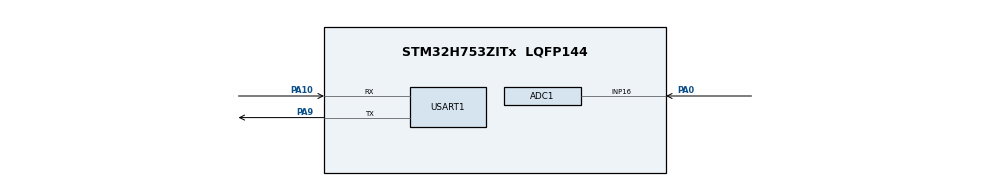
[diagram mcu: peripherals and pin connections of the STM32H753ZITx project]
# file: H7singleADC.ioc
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ADC1.Channel-0\#ChannelRegularConversion=ADC_CHANNEL_16
ADC1.ContinuousConvMode=ENABLE
ADC1.NbrOfConversionFlag=1
ADC1.OffsetNumber-0\#ChannelRegularConversion=ADC_OFFSET_NONE
ADC1.OffsetSignedSaturation-0\#ChannelRegularConversion=DISABLE
ADC1.Rank-0\#ChannelRegularConversion=1
ADC1.SamplingTime-0\#ChannelRegularConversion=ADC_SAMPLETIME_1CYCLE_5
ADC1.master=1
Dma.ADC1.0.Direction=DMA_PERIPH_TO_MEMORY
Dma.ADC1.0.EventEnable=DISABLE
Dma.ADC1.0.FIFOMode=DMA_FIFOMODE_DISABLE
Dma.ADC1.0.Instance=DMA1_Stream0
Dma.ADC1.0.MemDataAlignment=DMA_MDATAALIGN_HALFWORD
Dma.ADC1.0.MemInc=DMA_MINC_ENABLE
Dma.ADC1.0.Mode=DMA_CIRCULAR
Dma.ADC1.0.PeriphDataAlignment=DMA_PDATAALIGN_HALFWORD
Dma.ADC1.0.PeriphInc=DMA_PINC_DISABLE
Dma.ADC1.0.Polarity=HAL_DMAMUX_REQ_GEN_RISING
Dma.ADC1.0.Priority=DMA_PRIORITY_LOW
Dma.ADC1.0.RequestNumber=1
Dma.ADC1.0.SignalID=NONE
Dma.ADC1.0.SyncEnable=DISABLE
Dma.ADC1.0.SyncPolarity=HAL_DMAMUX_SYNC_NO_EVENT
Dma.ADC1.0.SyncRequestNumber=1
Dma.ADC1.0.SyncSignalID=NONE
Dma.Request0=ADC1
Mcu.Family=STM32H7
Mcu.Name=STM32H753ZITx
Mcu.Package=LQFP144
NVIC.ADC_IRQn=true\:0\:0\:false\:false\:true\:true\:true\:true
NVIC.DMA1_Stream0_IRQn=true\:0\:0\:false\:false\:true\:false\:true\:true
NVIC.PriorityGroup=NVIC_PRIORITYGROUP_4
PA0.Mode=IN16-Single-Ended
PA0.Signal=ADC1_INP16
PA10.Mode=Asynchronous
PA10.Signal=USART1_RX
PA9.Mode=Asynchronous
PA9.Signal=USART1_TX
ProjectManager.HeapSize=0x200
ProjectManager.StackSize=0x400
ProjectManager.TargetToolchain=STM32CubeIDE
RCC.ADCFreq_Value=129000000
RCC.APB1Freq_Value=64000000
RCC.APB2Freq_Value=64000000
RCC.APB3Freq_Value=64000000
RCC.APB4Freq_Value=64000000
RCC.CortexFreq_Value=64000000
RCC.HCLKFreq_Value=64000000
RCC.SYSCLKFreq_VALUE=64000000
RCC.USBFreq_Value=129000000
USART1.VirtualMode-Asynchronous=VM_ASYNC
board=custom

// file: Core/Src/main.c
/* USER CODE BEGIN Header */
/**
  ******************************************************************************
  * @file           : main.c
  * @brief          : Main program body
  ******************************************************************************
  * @attention
  *
  * Copyright (c) 2024 STMicroelectronics.
  * All rights reserved.
  *
  * This software is licensed under terms that can be found in the LICENSE file
  * in the root directory of this software component.
  * If no LICENSE file comes with this software, it is provided AS-IS.
  *
  ******************************************************************************
  */
/* USER CODE END Header */
#include "main.h"

/* USER CODE BEGIN PM */
#define ADC_BUF_LEN 4096
/* USER CODE END PM */

ADC_HandleTypeDef hadc1;
DMA_HandleTypeDef hdma_adc1;

UART_HandleTypeDef huart1;

/* USER CODE BEGIN PV */
uint16_t adc_buf[ADC_BUF_LEN];
/* USER CODE END PV */

void SystemClock_Config(void);
static void MX_GPIO_Init(void);
static void MX_DMA_Init(void);
static void MX_ADC1_Init(void);
static void MX_USART1_UART_Init(void);

int main(void)
{

  /* MCU Configuration--------------------------------------------------------*/

  /* Reset of all peripherals, Initializes the Flash interface and the Systick. */
  HAL_Init();

  /* Configure the system clock */
  SystemClock_Config();

  /* Initialize all configured peripherals */
  MX_GPIO_Init();
  MX_DMA_Init();
  MX_ADC1_Init();
  MX_USART1_UART_Init();
  /* USER CODE BEGIN 2 */
  HAL_ADC_Start_DMA(&hadc1, (uint32_t*)adc_buf, ADC_BUF_LEN);
  /* USER CODE END 2 */

  /* Infinite loop */
  while (1)
  {

  }
}

void SystemClock_Config(void)
{
  RCC_OscInitTypeDef RCC_OscInitStruct = {0};
  RCC_ClkInitTypeDef RCC_ClkInitStruct = {0};

  /** Supply configuration update enable
  */
  HAL_PWREx_ConfigSupply(PWR_LDO_SUPPLY);

  /** Configure the main internal regulator output voltage
  */
  __HAL_PWR_VOLTAGESCALING_CONFIG(PWR_REGULATOR_VOLTAGE_SCALE3);

  while(!__HAL_PWR_GET_FLAG(PWR_FLAG_VOSRDY)) {}

  /** Macro to configure the PLL clock source
  */
  __HAL_RCC_PLL_PLLSOURCE_CONFIG(RCC_PLLSOURCE_HSI);

  /** Initializes the RCC Oscillators according to the specified parameters
  * in the RCC_OscInitTypeDef structure.
  */
  RCC_OscInitStruct.OscillatorType = RCC_OSCILLATORTYPE_HSI;
  RCC_OscInitStruct.HSIState = RCC_HSI_DIV1;
  RCC_OscInitStruct.HSICalibrationValue = RCC_HSICALIBRATION_DEFAULT;
  RCC_OscInitStruct.PLL.PLLState = RCC_PLL_NONE;
  if (HAL_RCC_OscConfig(&RCC_OscInitStruct) != HAL_OK)
  {
    Error_Handler();
  }

  /** Initializes the CPU, AHB and APB buses clocks
  */
  RCC_ClkInitStruct.ClockType = RCC_CLOCKTYPE_HCLK|RCC_CLOCKTYPE_SYSCLK
                              |RCC_CLOCKTYPE_PCLK1|RCC_CLOCKTYPE_PCLK2
                              |RCC_CLOCKTYPE_D3PCLK1|RCC_CLOCKTYPE_D1PCLK1;
  RCC_ClkInitStruct.SYSCLKSource = RCC_SYSCLKSOURCE_HSI;
  RCC_ClkInitStruct.SYSCLKDivider = RCC_SYSCLK_DIV1;
  RCC_ClkInitStruct.AHBCLKDivider = RCC_HCLK_DIV1;
  RCC_ClkInitStruct.APB3CLKDivider = RCC_APB3_DIV1;
  RCC_ClkInitStruct.APB1CLKDivider = RCC_APB1_DIV1;
  RCC_ClkInitStruct.APB2CLKDivider = RCC_APB2_DIV1;
  RCC_ClkInitStruct.APB4CLKDivider = RCC_APB4_DIV1;

  if (HAL_RCC_ClockConfig(&RCC_ClkInitStruct, FLASH_LATENCY_1) != HAL_OK)
  {
    Error_Handler();
  }
}

static void MX_ADC1_Init(void)
{

  ADC_MultiModeTypeDef multimode = {0};
  ADC_ChannelConfTypeDef sConfig = {0};

  /* USER CODE BEGIN ADC1_Init 1 */
  // Enable ADC interrupt
  HAL_NVIC_SetPriority(ADC_IRQn, 0, 0);
  HAL_NVIC_EnableIRQ(ADC_IRQn);
  /* USER CODE END ADC1_Init 1 */

  /** Common config
  */
  hadc1.Instance = ADC1;
  hadc1.Init.ClockPrescaler = ADC_CLOCK_ASYNC_DIV4;
  hadc1.Init.Resolution = ADC_RESOLUTION_16B;
  hadc1.Init.ScanConvMode = ADC_SCAN_DISABLE;
  hadc1.Init.EOCSelection = ADC_EOC_SINGLE_CONV;
  hadc1.Init.LowPowerAutoWait = DISABLE;
  hadc1.Init.ContinuousConvMode = ENABLE;
  hadc1.Init.NbrOfConversion = 1;
  hadc1.Init.DiscontinuousConvMode = DISABLE;
  hadc1.Init.ExternalTrigConv = ADC_SOFTWARE_START;
  hadc1.Init.ExternalTrigConvEdge = ADC_EXTERNALTRIGCONVEDGE_NONE;
  hadc1.Init.ConversionDataManagement = ADC_CONVERSIONDATA_DR;
  hadc1.Init.Overrun = ADC_OVR_DATA_PRESERVED;
  hadc1.Init.LeftBitShift = ADC_LEFTBITSHIFT_NONE;
  hadc1.Init.OversamplingMode = DISABLE;
  if (HAL_ADC_Init(&hadc1) != HAL_OK)
  {
    Error_Handler();
  }

  /** Configure the ADC multi-mode
  */
  multimode.Mode = ADC_MODE_INDEPENDENT;
  if (HAL_ADCEx_MultiModeConfigChannel(&hadc1, &multimode) != HAL_OK)
  {
    Error_Handler();
  }

  /** Configure Regular Channel
  */
  sConfig.Channel = ADC_CHANNEL_16;
  sConfig.Rank = ADC_REGULAR_RANK_1;
  sConfig.SamplingTime = ADC_SAMPLETIME_1CYCLE_5;
  sConfig.SingleDiff = ADC_SINGLE_ENDED;
  sConfig.OffsetNumber = ADC_OFFSET_NONE;
  sConfig.Offset = 0;
  sConfig.OffsetSignedSaturation = DISABLE;
  if (HAL_ADC_ConfigChannel(&hadc1, &sConfig) != HAL_OK)
  {
    Error_Handler();
  }

}

static void MX_USART1_UART_Init(void)
{

  huart1.Instance = USART1;
  huart1.Init.BaudRate = 115200;
  huart1.Init.WordLength = UART_WORDLENGTH_8B;
  huart1.Init.StopBits = UART_STOPBITS_1;
  huart1.Init.Parity = UART_PARITY_NONE;
  huart1.Init.Mode = UART_MODE_TX_RX;
  huart1.Init.HwFlowCtl = UART_HWCONTROL_NONE;
  huart1.Init.OverSampling = UART_OVERSAMPLING_16;
  huart1.Init.OneBitSampling = UART_ONE_BIT_SAMPLE_DISABLE;
  huart1.Init.ClockPrescaler = UART_PRESCALER_DIV1;
  huart1.AdvancedInit.AdvFeatureInit = UART_ADVFEATURE_NO_INIT;
  if (HAL_UART_Init(&huart1) != HAL_OK)
  {
    Error_Handler();
  }
  if (HAL_UARTEx_SetTxFifoThreshold(&huart1, UART_TXFIFO_THRESHOLD_1_8) != HAL_OK)
  {
    Error_Handler();
  }
  if (HAL_UARTEx_SetRxFifoThreshold(&huart1, UART_RXFIFO_THRESHOLD_1_8) != HAL_OK)
  {
    Error_Handler();
  }
  if (HAL_UARTEx_DisableFifoMode(&huart1) != HAL_OK)
  {
    Error_Handler();
  }

}

static void MX_DMA_Init(void)
{

  /* DMA controller clock enable */
  __HAL_RCC_DMA1_CLK_ENABLE();

  /* DMA interrupt init */
  /* DMA1_Stream0_IRQn interrupt configuration */
  HAL_NVIC_SetPriority(DMA1_Stream0_IRQn, 0, 0);
  HAL_NVIC_EnableIRQ(DMA1_Stream0_IRQn);

}

static void MX_GPIO_Init(void)
{

  /* GPIO Ports Clock Enable */
  __HAL_RCC_GPIOA_CLK_ENABLE();

}

/* USER CODE BEGIN 4 */
//called when first half of buffer is filled
void HAL_ADC_CovHalfCpltCallback(ADC_HandleTypeDef *hadc) {
	HAL_Delay(0);
}
//called when full
void HAL_ADC_CovCpltCallback(ADC_HandleTypeDef *hadc) {
	uint16_t len = 0; int i;
	for (i=0; i < ADC_BUF_LEN; i++) {
		len+=snprintf(&adc_buf[len], sizeof(adc_buf)-len, "%d\n", adc_buf[i]);
	}
	HAL_UART_Transmit_DMA(&huart1, &adc_buf, len);
}
/* USER CODE END 4 */

void Error_Handler(void)
{
  __disable_irq();
  while (1)
  {
  }
}
